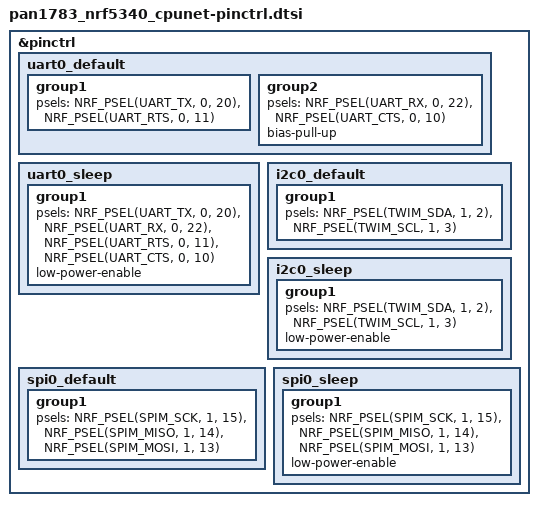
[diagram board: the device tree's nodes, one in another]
/*
 * Copyright (c) 2023 Panasonic Industrial Devices Europe GmbH
 * SPDX-License-Identifier: Apache-2.0
 */

&pinctrl {
	uart0_default: uart0_default {
		group1 {
			psels = <NRF_PSEL(UART_TX, 0, 20)>,
				<NRF_PSEL(UART_RTS, 0, 11)>;
		};

		group2 {
			psels = <NRF_PSEL(UART_RX, 0, 22)>,
				<NRF_PSEL(UART_CTS, 0, 10)>;
			bias-pull-up;
		};
	};

	uart0_sleep: uart0_sleep {
		group1 {
			psels = <NRF_PSEL(UART_TX, 0, 20)>,
				<NRF_PSEL(UART_RX, 0, 22)>,
				<NRF_PSEL(UART_RTS, 0, 11)>,
				<NRF_PSEL(UART_CTS, 0, 10)>;
			low-power-enable;
		};
	};

	i2c0_default: i2c0_default {
		group1 {
			psels = <NRF_PSEL(TWIM_SDA, 1, 2)>,
				<NRF_PSEL(TWIM_SCL, 1, 3)>;
		};
	};

	i2c0_sleep: i2c0_sleep {
		group1 {
			psels = <NRF_PSEL(TWIM_SDA, 1, 2)>,
				<NRF_PSEL(TWIM_SCL, 1, 3)>;
			low-power-enable;
		};
	};

	spi0_default: spi0_default {
		group1 {
			psels = <NRF_PSEL(SPIM_SCK, 1, 15)>,
				<NRF_PSEL(SPIM_MISO, 1, 14)>,
				<NRF_PSEL(SPIM_MOSI, 1, 13)>;
		};
	};

	spi0_sleep: spi0_sleep {
		group1 {
			psels = <NRF_PSEL(SPIM_SCK, 1, 15)>,
				<NRF_PSEL(SPIM_MISO, 1, 14)>,
				<NRF_PSEL(SPIM_MOSI, 1, 13)>;
			low-power-enable;
		};
	};
};
